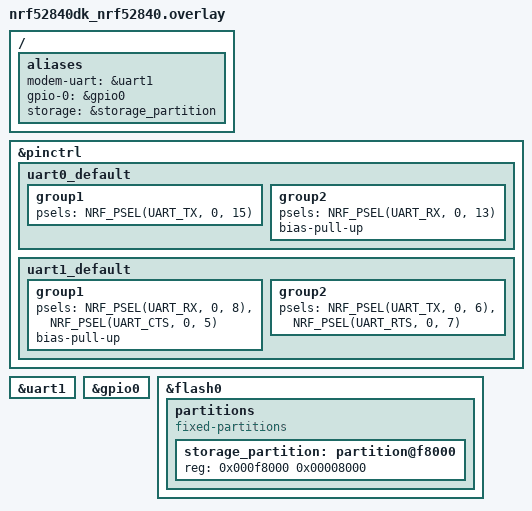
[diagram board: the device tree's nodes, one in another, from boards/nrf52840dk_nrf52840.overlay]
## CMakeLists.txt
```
# SPDX-License-Identifier: Apache-2.0

cmake_minimum_required(VERSION 3.20.0)
find_package(Zephyr REQUIRED HINTS $ENV{ZEPHYR_BASE})
project(scan_adv)

FILE(GLOB app_sources src/*.c)
target_sources(app PRIVATE ${app_sources})

add_definitions(-DDEBUG)

zephyr_library_include_directories(${ZEPHYR_BASE}/samples/bluetooth)

zephyr_library_include_directories("../../sdk/Interface")
zephyr_library_include_directories("../../sdk/sdkInc")
zephyr_library_include_directories("src")
zephyr_library_include_directories("src/MQTT")

target_sources(app PRIVATE src/osal/osal.c)
target_sources(app PRIVATE src/dev-if/dev-if.c)
target_sources(app PRIVATE src/modem-drv.c)
target_sources(app PRIVATE src/network-api.c)
target_sources(app PRIVATE src/at-commands.c)
target_sources(app PRIVATE src/httpStringBuilder.c)
target_sources(app PRIVATE src/flash-drv.c)
target_sources(app PRIVATE ../../sdk/sdkSrc/cJSON.c)
target_sources(app PRIVATE ../../sdk/sdkSrc/logger.c)
target_sources(app PRIVATE ../../sdk/sdkSrc/williotSdkJson.c)
target_sources(app PRIVATE ../../sdk/sdkSrc/upLink.c)
target_sources(app PRIVATE ../../sdk/sdkSrc/downLink.c)
target_sources(app PRIVATE ../../sdk/sdkSrc/sdkConfigurations.c)
target_sources(app PRIVATE ../../sdk/sdkSrc/mqttTopics.c)
target_sources(app PRIVATE ../../sdk/sdkSrc/networkManager.c)
target_sources(app PRIVATE ../../sdk/sdkSrc/serviceDiscovery.c)

# This for MQTT
target_sources(app PRIVATE src/MQTT/MQTTConnectClient.c)
target_sources(app PRIVATE src/MQTT/MQTTConnectServer.c)
target_sources(app PRIVATE src/MQTT/MQTTDeserializePublish.c)
target_sources(app PRIVATE src/MQTT/MQTTFormat.c)
target_sources(app PRIVATE src/MQTT/MQTTPacket.c)
target_sources(app PRIVATE src/MQTT/MQTTSerializePublish.c)
target_sources(app PRIVATE src/MQTT/MQTTSubscribeClient.c)
target_sources(app PRIVATE src/MQTT/MQTTSubscribeServer.c)
target_sources(app PRIVATE src/MQTT/MQTTUnsubscribeClient.c)
target_sources(app PRIVATE src/MQTT/MQTTSubscribeServer.c)
target_sources(app PRIVATE src/MQTT/MQTTUnsubscribeServer.c)
```

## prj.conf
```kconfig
CONFIG_BT=y
CONFIG_BT_BROADCASTER=y
CONFIG_BT_OBSERVER=y
CONFIG_BT_DEBUG_LOG=y
CONFIG_BT_DEVICE_NAME="GatewayOfhappiness"
CONFIG_HEAP_MEM_POOL_SIZE=8192
CONFIG_UART_INTERRUPT_DRIVEN=y
CONFIG_ASSERT=y
CONFIG_EVENTS=y
CONFIG_NEWLIB_LIBC=y
CONFIG_NEWLIB_LIBC_FLOAT_PRINTF=y

CONFIG_FLASH=y
CONFIG_FLASH_MAP=y
CONFIG_MPU_ALLOW_FLASH_WRITE=y
```

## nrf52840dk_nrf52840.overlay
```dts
&pinctrl {
	uart0_default: uart0_default {
		group1 {
			psels = <NRF_PSEL(UART_TX, 0, 15)>;
		};
		group2 {
			psels = <NRF_PSEL(UART_RX, 0, 13)>;
			bias-pull-up;
		};
	};

	uart1_default: uart1_default {
		group1 {
			psels = <NRF_PSEL(UART_RX, 0, 8)>,
				<NRF_PSEL(UART_CTS, 0, 5)>;
			bias-pull-up;
		};
		group2 {
			psels = <NRF_PSEL(UART_TX, 0, 6)>,
				<NRF_PSEL(UART_RTS, 0, 7)>;
		};
	};

};

&uart1{
	label = "MODEM_UART";
	status = "okay";
};

&gpio0 {
	label = "GPIO_0";
	status = "okay";
};

&flash0 {

	partitions {
		compatible = "fixed-partitions";
		#address-cells = <1>;
		#size-cells = <1>;

		storage_partition: partition@f8000 {
			label = "storage";
			status = "okay";
			reg = <0x000f8000 0x00008000>;
		};
	};
};
```

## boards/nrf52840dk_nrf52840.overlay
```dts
/ {
    aliases {
        modem-uart = &uart1;
        gpio-0 = &gpio0;
        storage = &storage_partition;
    };
};

&pinctrl {
	uart0_default: uart0_default {
		group1 {
			psels = <NRF_PSEL(UART_TX, 0, 15)>;
		};
		group2 {
			psels = <NRF_PSEL(UART_RX, 0, 13)>;
			bias-pull-up;
		};
	};

	uart1_default: uart1_default {
		group1 {
			psels = <NRF_PSEL(UART_RX, 0, 8)>,
				<NRF_PSEL(UART_CTS, 0, 5)>;
			bias-pull-up;
		};
		group2 {
			psels = <NRF_PSEL(UART_TX, 0, 6)>,
				<NRF_PSEL(UART_RTS, 0, 7)>;
		};
	};

};

&uart1{
	status = "okay";
};

&gpio0 {
	status = "okay";
};

&flash0 {

	partitions {
		compatible = "fixed-partitions";
		#address-cells = <1>;
		#size-cells = <1>;

		storage_partition: partition@f8000 {
			status = "okay";
			reg = <0x000f8000 0x00008000>;
		};
	};
};
```

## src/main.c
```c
/* main.c - Application main entry point */

/*
 * Copyright (c) 2015-2016 Intel Corporation
 *
 * SPDX-License-Identifier: Apache-2.0
 */
#include <stdio.h>
#include <stdint.h>
#include <stddef.h>
#include <assert.h>

#include <zephyr/types.h>
#include <zephyr/sys/util.h>
#include <zephyr/bluetooth/bluetooth.h>
#include <zephyr/bluetooth/hci.h>

#include "osal.h"
#include "dev-if.h"
#include "network-api.h"
#include "williotSdkJson.h"
#include "logger.h"
#include "upLink.h"
#include "downLink.h"
#include "sdkConfigurations.h"
#include "mqttTopics.h"
#include "networkManager.h"

void main(void)
{
	dev_handle localDevHandle;
	dev_handle bleDevHandle;
	SDK_STAT sdkStatus = 0;

	OsalInit(); // System initialization starts here

	sdkStatus = ConfigurationInit();
	assert(sdkStatus == SDK_SUCCESS);

	// We are expecting NULL because we don't have any local device on current platform.
	localDevHandle = DevInit(DEV_LOCAL_FIRST);
	// assert(localDevHandle);

	bleDevHandle = DevInit(DEV_BLE);
	assert(bleDevHandle);

	sdkStatus = JsonHooksInit();
	assert(sdkStatus == SDK_SUCCESS);

	sdkStatus = UpLinkInit(bleDevHandle, localDevHandle);
	assert(sdkStatus == SDK_SUCCESS);

	sdkStatus = LoggerInit();
	assert(sdkStatus == SDK_SUCCESS);

	sdkStatus = DownLinkInit(bleDevHandle, localDevHandle);
	assert(sdkStatus == SDK_SUCCESS);

	sdkStatus = NetworkManagerInit();
	assert(sdkStatus == SDK_SUCCESS);
	
    sdkStatus = NetworkInit();
    assert(sdkStatus == SDK_SUCCESS);

	OsalStart(); // System therads released here

	OsalSleep(UINT32_MAX);
}
```

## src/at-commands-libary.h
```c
#ifndef _AT_COMMANDS_LIBARY_H
#define _AT_COMMANDS_LIBARY_H

typedef enum{
    MODE_DISABLE_TIME_ZONE_CHANGE           = 0,
    MODE_ENABLE_TIME_ZONE_CHANGE            = 1,
    MODE_ENABLE_EXTENDED_TIME_ZONE_CHANGE   = 2
} eModeOfTimeZoneReporting;

typedef enum{
    MODE_DISABLE_AUTOMATIC_TIME_ZONE_UPDATE                         = 0,
    MODE_ENABLE_AUTOMATIC_TIME_ZONE_UPDATE                          = 1,
    MODE_ENABLE_AUTOMATIC_TIME_ZONE_UPDATE_AND_UPDATE_LOCAL_TIME    = 3
} eModeOfAutomaticTimeZoneUpdate;

typedef enum{
    EXTENDED_CONFIGURE_RATS_SEARCHING_SEQUENCE,
    EXTENDED_CONFIGURE_RATS_TO_BE_SEARCHED,
    EXTENDED_CONFIGURE_NETWORK_SEARCH_UNDER_LTE_RAT,

    EXTENDED_CONFIGURE_NUM
} eExtendedConfigurationCommands;

typedef enum{
    PDP_TYPE_IPV4,
    PDP_TYPE_PPP,
    PDP_TYPE_IPV6,
    PDP_TYPE_IPV4V6,

    PDP_TYPE_NUM
} ePdpType;

typedef enum{
    HTTP_CONFIGURATION_PDP_CONTEXT_ID,
    HTTP_CONFIGURATION_REQUEST_HEADER,
    HTTP_CONFIGURATION_RESPOSNSE_HEADER,
    HTTP_CONFIGURATION_CONTENT_TYPE,

    HTTP_CONFIGURATION_NUM
} eHttpConfigurationCommands;

typedef enum{
    NETWORK_REGISTRATION_DISABLE = 0,
    NETWORK_REGISTRATION_ENABLE = 1,
    NETWORK_REGISTRATION_AND_LOCATION_INFORMATION_ENABLE = 2,
    NETWORK_REGISTRATION_AND_LOCATION_INFORMATION_UE_ENABLE = 4,
}eNetworkRegistrationStatus;

typedef enum{
    QUERY_LATEST_TIME_SYNCHRONIZED_THROUGH_NETWORK = 0,
    QUERY_THE_CURRENT_GMT_TIME = 1,
    QUERY_THE_CURRENT_LOCAL_TIME = 2,
}eQueryNetworkTimeMode;

typedef enum{
    MQTT_ACCESS_BUFFER_ACCESS = 0,
    MQTT_ACCESS_DIRECT_PUSH = 1,
    MQTT_ACCESS_TRANSPARENT = 2,
}eMqttAccessMode;

typedef struct{
    eModeOfTimeZoneReporting mode;
}AtCtzrParams;

typedef struct{
    eModeOfAutomaticTimeZoneUpdate mode;
}AtCtzuParams;

typedef struct{
    eExtendedConfigurationCommands cmd;
    char * mode;
    int effect;
}AtQcfgParams;

typedef struct{
    int cid;
    ePdpType type;
    char * apn;
}AtCgdcontParams;

typedef struct{
    int getImei;
}AtCgsn;

typedef struct{
    eNetworkRegistrationStatus status;
}AtCereg;

typedef struct{
    eQueryNetworkTimeMode mode;
}AtQlts;

typedef struct{
    int contextId;
    char * host;
}AtQping;

typedef struct{
    eHttpConfigurationCommands cmd;
    int value;
}AtQhttpcfg;

typedef struct{
    int urlLength;
    int urlTimeout;
}AtQhttpurl;

typedef struct{
    int postBodySize;
    int inputTimeout;
    int responseTimeout;
}AtQhttppost;

typedef struct{
    int pdpctxId;
    int sslctxId;
    int clientId;
    const char * serverAddr;
    int serverPort;
    eMqttAccessMode accessMode;
}AtQsslopen;

typedef struct{
    int clientId;
    int payloadLength;
}AtQsslsend;

typedef struct{
    int clientId;
    int receiveLength;
}AtQsslrecv;

typedef struct{
    int clientId;
    eMqttAccessMode accessMode;
}AtQiswtmd;

#endif //_AT_COMMANDS_LIBARY_H
```

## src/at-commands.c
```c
#include "at-commands.h"
#include <assert.h>
#include <string.h>

#define FULL_MESSAGE_BUFFER_SIZE    (2048)
#define COMMAND_PREFIX_SYMBOL       ('+')
#define COMMAND_READ_SYMBOL         ('?')
#define COMMAND_SEPERATE_SYMBOL     (',')
#define COMMAND_EXECUTE_SYMBOL      ('=')
#define COMMAND_STRING_SYMBOL       ('\"')
#define COMMNAD_END_OF_LINE         ("\r\n")
#define COMMAND_KEY_VALUE_SEPERATE  (':')

#define SIZE_OF_POST_PRE_RESPOND    (2)
#define RESPONSE_SIZE(size)         ((size) + SIZE_OF_POST_PRE_RESPOND)

static const char * s_atStr = "AT";

static const char * s_atCmdsTable[AT_CMD_NUM] = {
	[AT_CMD_TEST]       = "",
	[AT_CMD_QCCID]      = "QCCID",
	[AT_CMD_CTZR]       = "CTZR",
	[AT_CMD_CTZU]       = "CTZU",
    [AT_CMD_QCFG]       = "QCFG",
    [AT_CMD_CGDCONT]    = "CGDCONT",
    [AT_CMD_CGSN]       = "CGSN",
	[AT_CMD_CEREG]      = "CEREG",
	[AT_CMD_COPS]       = "COPS",
    [AT_CMD_QCSQ]       = "QCSQ",
    [AT_CMD_QLTS]       = "QLTS",
    [AT_CMD_QPING]      = "QPING",
    [AT_CMD_QHTTPCFG]   = "QHTTPCFG",
    [AT_CMD_QHTTPURL]   = "QHTTPURL",
    [AT_CMD_QHTTPPOST]  = "QHTTPPOST",
    [AT_CMD_QHTTPGET]   = "QHTTPGET",
    [AT_CMD_QHTTPPUT]   = "QHTTPPUT",
    [AT_CMD_QHTTPREAD]  = "QHTTPREAD",
    [AT_CMD_QSSLOPEN]   = "QSSLOPEN",
    [AT_CMD_QSSLSEND]   = "QSSLSEND",
    [AT_CMD_QSSLRECV]   = "QSSLRECV",
    [AT_CMD_QISWTMD]     ="QISWTMD",
};

static const char * s_atQcfgExtConfgCmndTable[EXTENDED_CONFIGURE_NUM] = {
    [EXTENDED_CONFIGURE_RATS_SEARCHING_SEQUENCE]         = "\"nwscanseq\"",
    [EXTENDED_CONFIGURE_RATS_TO_BE_SEARCHED]             = "\"nwscanmode\"",
    [EXTENDED_CONFIGURE_NETWORK_SEARCH_UNDER_LTE_RAT]    = "\"iotopmode\"",
};

static const char * s_atCgdcontPdpTypeTable[PDP_TYPE_NUM] = {
    [PDP_TYPE_IPV4]     = "\"IPV4\"",
    [PDP_TYPE_PPP]      = "\"PPP\"",
    [PDP_TYPE_IPV6]     = "\"IPV6\"",
    [PDP_TYPE_IPV4V6]   = "\"IPV4V6\"",
};

static const char * s_atQhttpcfgCmndTable[HTTP_CONFIGURATION_NUM] = {
    [HTTP_CONFIGURATION_PDP_CONTEXT_ID]     = "\"contextid\"",
    [HTTP_CONFIGURATION_REQUEST_HEADER]     = "\"requestheader\"",
    [HTTP_CONFIGURATION_RESPOSNSE_HEADER]   = "\"responseheader\"",
    [HTTP_CONFIGURATION_CONTENT_TYPE]       = "\"contenttype\""
};

static uint8_t bufferForTesting[FULL_MESSAGE_BUFFER_SIZE];

static inline int writeCtzr(const AtCmndsParams* cmndParams, int offset)
{
    return sprintf((bufferForTesting + offset), "%d", cmndParams->atCtzrParams.mode);
}

static inline int writeCtzu(const AtCmndsParams* cmndParams, int offset)
{
    return sprintf((bufferForTesting + offset), "%d", cmndParams->atCtzuParams.mode);
}

static inline int writeQcfg(const AtCmndsParams * cmndParams, int * offset)
{
    (*offset) += sprintf((bufferForTesting + (*offset)), "%s", s_atQcfgExtConfgCmndTable[cmndParams->atQcfgParams.cmd]);
    (*offset) += sprintf((bufferForTesting + (*offset)), "%c", COMMAND_SEPERATE_SYMBOL);
    (*offset) += sprintf((bufferForTesting + (*offset)), "%s", cmndParams->atQcfgParams.mode);
    (*offset) += sprintf((bufferForTesting + (*offset)), "%c", COMMAND_SEPERATE_SYMBOL);
    return sprintf((bufferForTesting + (*offset)), "%d", cmndParams->atQcfgParams.effect);
}

static inline int writeCgdcont(const AtCmndsParams * cmndParams, int * offset)
{
    (*offset) += sprintf((bufferForTesting + (*offset)), "%d", cmndParams->atCgdcontParams.cid);
    (*offset) += sprintf((bufferForTesting + (*offset)), "%c", COMMAND_SEPERATE_SYMBOL);
    (*offset) += sprintf((bufferForTesting + (*offset)), "%s", s_atCgdcontPdpTypeTable[cmndParams->atCgdcontParams.type]);
    (*offset) += sprintf((bufferForTesting + (*offset)), "%c", COMMAND_SEPERATE_SYMBOL);
    (*offset) += sprintf((bufferForTesting + (*offset)), "%c", COMMAND_STRING_SYMBOL);
    (*offset) += sprintf((bufferForTesting + (*offset)), "%s", cmndParams->atCgdcontParams.apn);
    return sprintf((bufferForTesting + (*offset)), "%c", COMMAND_STRING_SYMBOL);
}

static inline int writeCereg(const AtCmndsParams * cmndParams, int offset)
{
    return sprintf((bufferForTesting + offset), "%d", cmndParams->atCereg.status);
}

static inline int writeQlts(const AtCmndsParams * cmndParams, int offset)
{
    return sprintf((bufferForTesting + offset), "%d", cmndParams->atQlts.mode);
}

static inline int writeQping(const AtCmndsParams * cmndParams, int * offset)
{
    (*offset) += sprintf((bufferForTesting + (*offset)), "%d", cmndParams->atQping.contextId);
    (*offset) += sprintf((bufferForTesting + (*offset)), "%c", COMMAND_SEPERATE_SYMBOL);
    (*offset) += sprintf((bufferForTesting + (*offset)), "%c", COMMAND_STRING_SYMBOL);
    (*offset) += sprintf((bufferForTesting + (*offset)), "%s", cmndParams->atQping.host);
    return sprintf((bufferForTesting + (*offset)), "%c", COMMAND_STRING_SYMBOL);
}

static inline int writeQhttpcfg(const AtCmndsParams * cmndParams, int * offset)
{
    (*offset) += sprintf((bufferForTesting + (*offset)), "%s", s_atQhttpcfgCmndTable[cmndParams->atQhttpcfg.cmd]);
    (*offset) += sprintf((bufferForTesting + (*offset)), "%c", COMMAND_SEPERATE_SYMBOL);
    return sprintf((bufferForTesting + (*offset)), "%d", cmndParams->atQhttpcfg.value);
}

static inline int writeQhttpurl(const AtCmndsParams * cmndParams, int * offset)
{
    (*offset) += sprintf((bufferForTesting + (*offset)), "%d", cmndParams->atQhttpurl.urlLength);
    (*offset) += sprintf((bufferForTesting + (*offset)), "%c", COMMAND_SEPERATE_SYMBOL);
    return sprintf((bufferForTesting + (*offset)), "%d", cmndParams->atQhttpurl.urlTimeout);
}

static inline int writeQhttppost(const AtCmndsParams * cmndParams, int * offset)
{
    (*offset) += sprintf((bufferForTesting + (*offset)), "%d", cmndParams->atQhttppost.postBodySize);
    (*offset) += sprintf((bufferForTesting + (*offset)), "%c", COMMAND_SEPERATE_SYMBOL);
    (*offset) += sprintf((bufferForTesting + (*offset)), "%d", cmndParams->atQhttppost.inputTimeout);
    (*offset) += sprintf((bufferForTesting + (*offset)), "%c", COMMAND_SEPERATE_SYMBOL);
    return sprintf((bufferForTesting + (*offset)), "%d", cmndParams->atQhttppost.responseTimeout);
}

static inline int writeQhttpget(const AtCmndsParams * cmndParams, int offset)
{
    return sprintf((bufferForTesting + offset), "%d", cmndParams->atQhttpurl.urlTimeout);
}

static inline int writeQhttread(const AtCmndsParams * cmndParams, int offset)
{
    return sprintf((bufferForTesting + offset), "%d", cmndParams->atQhttpurl.urlTimeout);
}

static inline int writeQsslopen(const AtCmndsParams * cmndParams, int * offset)
{
    (*offset) += sprintf((bufferForTesting + (*offset)), "%d", cmndParams->atQsslopen.pdpctxId);
    (*offset) += sprintf((bufferForTesting + (*offset)), "%c", COMMAND_SEPERATE_SYMBOL);
    (*offset) += sprintf((bufferForTesting + (*offset)), "%d", cmndParams->atQsslopen.sslctxId);
    (*offset) += sprintf((bufferForTesting + (*offset)), "%c", COMMAND_SEPERATE_SYMBOL);
    (*offset) += sprintf((bufferForTesting + (*offset)), "%d", cmndParams->atQsslopen.clientId);
    (*offset) += sprintf((bufferForTesting + (*offset)), "%c", COMMAND_SEPERATE_SYMBOL);
    (*offset) += sprintf((bufferForTesting + (*offset)), "%c", COMMAND_STRING_SYMBOL);
    (*offset) += sprintf((bufferForTesting + (*offset)), "%s", cmndParams->atQsslopen.serverAddr);
    (*offset) += sprintf((bufferForTesting + (*offset)), "%c", COMMAND_STRING_SYMBOL);
    (*offset) += sprintf((bufferForTesting + (*offset)), "%c", COMMAND_SEPERATE_SYMBOL);
    (*offset) += sprintf((bufferForTesting + (*offset)), "%d", cmndParams->atQsslopen.serverPort);
    (*offset) += sprintf((bufferForTesting + (*offset)), "%c", COMMAND_SEPERATE_SYMBOL);
    return sprintf((bufferForTesting + (*offset)), "%d", cmndParams->atQsslopen.accessMode); 
}

static inline int writeQsslsend(const AtCmndsParams * cmndParams, int * offset)
{
    (*offset) += sprintf((bufferForTesting + (*offset)), "%d", cmndParams->atQsslsend.clientId);
    (*offset) += sprintf((bufferForTesting + (*offset)), "%c", COMMAND_SEPERATE_SYMBOL);
    return sprintf((bufferForTesting + (*offset)), "%d", cmndParams->atQsslsend.payloadLength);  
}

static inline int writeQsslrecv(const AtCmndsParams * cmndParams, int * offset)
{
    (*offset) += sprintf((bufferForTesting + (*offset)), "%d", cmndParams->atQsslrecv.clientId);
    (*offset) += sprintf((bufferForTesting + (*offset)), "%c", COMMAND_SEPERATE_SYMBOL);
    return sprintf((bufferForTesting + (*offset)), "%d", cmndParams->atQsslrecv.receiveLength);  
}

static inline int writeQiswtmd(const AtCmndsParams * cmndParams, int * offset)
{
    (*offset) += sprintf((bufferForTesting + (*offset)), "%d", cmndParams->atQiswtmd.clientId);
    (*offset) += sprintf((bufferForTesting + (*offset)), "%c", COMMAND_SEPERATE_SYMBOL);
    return sprintf((bufferForTesting + (*offset)), "%d", cmndParams->atQiswtmd.accessMode);  
}

SDK_STAT AtTestCmd()
{
    // For now not implemeted because no test commands, always fails
    // TODO: implement
    return SDK_FAILURE;
}

SDK_STAT AtReadCmd(const eAtCmds atCmd)
{
    int offset = 0;

    if(!(0 <= atCmd && atCmd < AT_CMD_NUM))
    {
        return SDK_INVALID_PARAMS;
    }
    assert(s_atCmdsTable[atCmd]);

    offset += sprintf((bufferForTesting + offset), "%s", s_atStr);
    offset += sprintf((bufferForTesting + offset), "%c", COMMAND_PREFIX_SYMBOL);
    offset += sprintf((bufferForTesting + offset), "%s", s_atCmdsTable[atCmd]);
    offset += sprintf((bufferForTesting + offset), "%c", COMMAND_READ_SYMBOL);
    offset += sprintf((bufferForTesting + offset), "%s", COMMNAD_END_OF_LINE);

    return ModemSend(bufferForTesting, offset);
}

SDK_STAT AtWriteCmd(const eAtCmds atCmd, const AtCmndsParams * cmndParams)
{
    int offset = 0;

    if(!(0 <= atCmd && atCmd < AT_CMD_NUM) || !cmndParams)
    {
      return SDK_INVALID_PARAMS;  
    }
    assert(s_atCmdsTable[atCmd]);

    offset += sprintf((bufferForTesting + offset), "%s", s_atStr);
    offset += sprintf((bufferForTesting + offset), "%c", COMMAND_PREFIX_SYMBOL);
    offset += sprintf((bufferForTesting + offset), "%s", s_atCmdsTable[atCmd]);
    offset += sprintf((bufferForTesting + offset), "%c", COMMAND_EXECUTE_SYMBOL);

    switch(atCmd)
    {
        case AT_CMD_CTZR:
            offset += writeCtzr(cmndParams, offset);
            break;

        case AT_CMD_CTZU:
            offset += writeCtzu(cmndParams, offset);
            break;

        case AT_CMD_QCFG:
            offset += writeQcfg(cmndParams, &offset);
            break;

        case AT_CMD_CGDCONT:
            offset += writeCgdcont(cmndParams, &offset);
            break;

        case AT_CMD_CEREG:
            offset += writeCereg(cmndParams, offset);
            break;

        case AT_CMD_QLTS:
            offset += writeQlts(cmndParams, offset);
            break;

        case AT_CMD_QPING:
            offset += writeQping(cmndParams, &offset);
            break;

        case AT_CMD_QHTTPCFG:
            offset += writeQhttpcfg(cmndParams, &offset);
            break;

        case AT_CMD_QHTTPURL:
            offset += writeQhttpurl(cmndParams, &offset);
            break;

        case AT_CMD_QHTTPPOST:
            offset += writeQhttppost(cmndParams, &offset);
            break;

        case AT_CMD_QHTTPGET:
            offset += writeQhttpget(cmndParams, offset);
            break;

        case AT_CMD_QHTTPPUT:
            offset += writeQhttppost(cmndParams, &offset);
        break;

        case AT_CMD_QHTTPREAD:
            offset += writeQhttread(cmndParams, offset);
            break;

        case AT_CMD_QSSLOPEN:
            offset += writeQsslopen(cmndParams, &offset);
            break;

        case AT_CMD_QSSLSEND:
            offset += writeQsslsend(cmndParams, &offset);
            break;

        case AT_CMD_QSSLRECV:
            offset += writeQsslrecv(cmndParams, &offset);
            break;

        case AT_CMD_QISWTMD:
            offset += writeQiswtmd(cmndParams, &offset);
            break;

        default:
            return SDK_INVALID_PARAMS;  
    }

    offset += sprintf((bufferForTesting + offset), "%s", COMMNAD_END_OF_LINE);

    return ModemSend(bufferForTesting, offset);
}

SDK_STAT AtExecuteCmd(const eAtCmds atCmd)
{
    int offset = 0;

    if(!(0 <= atCmd && atCmd < AT_CMD_NUM))
    {
        return SDK_INVALID_PARAMS;
    }
    assert(s_atCmdsTable[atCmd]);

    offset += sprintf((bufferForTesting + offset), "%s", s_atStr);
    if(atCmd != AT_CMD_TEST)
    {
        offset += sprintf((bufferForTesting + offset), "%c", COMMAND_PREFIX_SYMBOL);
        offset += sprintf((bufferForTesting + offset), "%s", s_atCmdsTable[atCmd]);
    }
    offset += sprintf((bufferForTesting + offset), "%s", COMMNAD_END_OF_LINE);

    return ModemSend(bufferForTesting, offset);
}

SDK_STAT atEnumToResponseString(eAtCmds atCmd, char * responseBuffer, uint16_t bufferSize)
{
    assert(s_atCmdsTable[atCmd]);
    if(atCmd >= AT_CMD_NUM || !responseBuffer || (bufferSize == 0))
    {
        return SDK_INVALID_PARAMS;
    }

    uint16_t stringSize = strlen(s_atCmdsTable[atCmd]);
    uint16_t index = 0;

    if(bufferSize <= RESPONSE_SIZE(stringSize))
    {
        return SDK_INVALID_PARAMS;
    }

    responseBuffer[index++] = COMMAND_PREFIX_SYMBOL;
    index += sprintf((responseBuffer + index), "%s",s_atCmdsTable[atCmd]);
    responseBuffer[index++] = COMMAND_KEY_VALUE_SEPERATE;
    responseBuffer[index++] = '\0';

    return SDK_SUCCESS;

}
```

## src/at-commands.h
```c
#ifndef _AT_COMMANDS_H
#define _AT_COMMANDS_H

#include "at-commands-libary.h"
#include "modem-drv.h"

#include <stdio.h>
#include <stdint.h>

#define TURN_ON_AT_CMD_ECHO         "ATE1\r\n"
#define TURN_OFF_AT_CMD_ECHO        "ATE0\r\n"

typedef enum{
    AT_CMD_TEST,
    AT_CMD_QCCID,
    AT_CMD_CTZR,
    AT_CMD_CTZU,
    AT_CMD_QCFG,
    AT_CMD_CGDCONT,
    AT_CMD_CGSN,
    AT_CMD_CEREG,
    AT_CMD_COPS,
    AT_CMD_QCSQ,
    AT_CMD_QLTS,
    AT_CMD_QPING,
    AT_CMD_QHTTPCFG,
    AT_CMD_QHTTPURL,
    AT_CMD_QHTTPPOST,
    AT_CMD_QHTTPGET,
    AT_CMD_QHTTPPUT,
    AT_CMD_QHTTPREAD,
    AT_CMD_QSSLOPEN,
    AT_CMD_QSSLSEND,
    AT_CMD_QSSLRECV,
    AT_CMD_QISWTMD,

    AT_CMD_NUM
} eAtCmds;

typedef union {
    AtCtzrParams    atCtzrParams;
    AtCtzuParams    atCtzuParams;
    AtQcfgParams    atQcfgParams;
    AtCgdcontParams atCgdcontParams;
    AtCgsn          atCgsn;
    AtCereg         atCereg;
    AtQlts          atQlts;
    AtQping         atQping;
    AtQhttpcfg      atQhttpcfg;
    AtQhttpurl      atQhttpurl;
    AtQhttppost     atQhttppost;
    AtQsslopen      atQsslopen;
    AtQsslsend      atQsslsend;
    AtQsslrecv      atQsslrecv;
    AtQiswtmd       atQiswtmd;

}AtCmndsParams;

/**
 * @brief AT type test command function
 * 
 * @return SDK_SUCCESS if command was sent succefull
 */
SDK_STAT AtTestCmd();

/**
 * @brief AT type read command function
 * 
 * @param atCmd enum of requested command
 *
 * @return SDK_INVALID_PARAMS if enum not in bounds.
 * @return SDK_FAILURE if internal bug occurred(higher level should assert).
 * @return SDK_SUCCESS if command was sent succefully.
 */
SDK_STAT AtReadCmd(const eAtCmds atCmd);

/**
 * @brief AT type write command function
 * 
 * @param atCmd enum of requested command
 * @param cmndParams pointer to parameters of command
 *
 * @return SDK_INVALID_PARAMS if enum not in bounds or null pointer.
 * @return SDK_FAILURE if internal bug occurred(higher level should assert).
 * @return SDK_SUCCESS if command was sent succefully.
 */
SDK_STAT AtWriteCmd(const eAtCmds atCmd, const AtCmndsParams * cmndParams);

/**
 * @brief AT type execution command function
 * 
 * @param atCmd enum of requested command
 *
 * @return SDK_INVALID_PARAMS if enum not in bounds.
 * @return SDK_FAILURE if internal bug occurred(higher level should assert).
 * @return SDK_SUCCESS if command was sent succefully.
 */
SDK_STAT AtExecuteCmd(const eAtCmds atCmd);

/**
 * @brief Convert enum to modem response string.
 * 
 * @param atCmd enum of requested command
 * @param responseBuffer pointer to buffer to save the response string.
 * @param bufferSize size of buffer.
 * 
 * @return SDK_INVALID_PARAMS if null ptr or at command doesnt exist or buffer size is to short.
 * @return SDK_SUCCESS if response built successfully.
 */
SDK_STAT atEnumToResponseString(eAtCmds atCmd, char * responseBuffer, uint16_t bufferSize);

#endif //_AT_COMMANDS_H
```

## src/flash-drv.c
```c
#include <zephyr/drivers/flash.h>
#include <zephyr/storage/flash_map.h>

#include "flash-drv.h"

const static struct flash_area * s_storageArea = NULL;

inline static off_t getPageOffset(eFlashPage flashPage)
{
    return (off_t)(SIZE_OF_FLASH_PAGE * flashPage);
}

SDK_STAT FlashInit()
{
    int err = 0;
    static bool isFlashOpen = false;
 
    if(!isFlashOpen)
    {
        err = flash_area_open(FLASH_AREA_ID(storage), &s_storageArea);
        isFlashOpen = true;
    }

    return (err ? SDK_FAILURE : SDK_SUCCESS);
}

SDK_STAT FlashRead(eFlashPage flashPage, void * savePageAdd)
{
    if(!savePageAdd || (flashPage >= FLASH_PAGE_NUM)) // recheck this maybe error
    {
        return SDK_INVALID_PARAMS;
    }

    int err = flash_area_read(s_storageArea, getPageOffset(flashPage), savePageAdd, SIZE_OF_FLASH_PAGE);
    if(err)
    {
        return SDK_FAILURE;
    }

    return SDK_SUCCESS;
}

SDK_STAT FlashWrite(eFlashPage flashPage, const void * loadStrAdd, size_t sizeOfLoadStr)
{
    if(!loadStrAdd || (flashPage >= FLASH_PAGE_NUM)) // recheck this maybe error
    {
        return SDK_INVALID_PARAMS;
    }

    int ans = flash_area_write(s_storageArea, getPageOffset(flashPage), loadStrAdd, sizeOfLoadStr);
    if(ans)
    {
        return SDK_FAILURE;
    }

    return SDK_SUCCESS;
}

SDK_STAT FlashErase(eFlashPage flashPage)
{
    int ans = flash_area_erase(s_storageArea, getPageOffset(flashPage), SIZE_OF_FLASH_PAGE);
    if(ans)
    {
        return SDK_FAILURE;
    }

    return SDK_SUCCESS;
}
```

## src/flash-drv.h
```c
#ifndef _FLASH_DRV_H_
#define _FLASH_DRV_H_

#include "sdk_common.h"

#define SIZE_OF_WORD                (4)
#define SIZE_OF_FLASH_PAGE          (4096)

typedef enum{
    FLASH_PAGE_CONFIGURATION,
    FLASH_PAGE_TOKENS,

    FLASH_PAGE_NUM
} eFlashPage;

/**
 * @brief Initialize the Flash driver.
 * 
 * @return SDK_FAILURE if flash failed to open
 * @return SDK_SUCCESS if flash opened successfully.
 */
SDK_STAT FlashInit();

/**
 * @brief Read page from flash.
 * 
 * @param flashPage enum of the requested flash page.
 * @param savePageAdd pointer to buffer to store the readen page.
 * 
 * @return SDK_INVALID_PARAMS if null ptr or bad page was passed.
 * @return SDK_FAILURE if internal flash error accord.
 * @return SDK_SUCCESS if initialized successfully.
 */
SDK_STAT FlashRead(eFlashPage flashPage, void * savePageAdd);

/**
 * @brief Write page to flash.
 * 
 * @param flashPage enum of the requested flash page.
 * @param loadStrAdd pointer to buffer that have data to write.
 * @param sizeOfLoadStr size of data to write.
 * 
 * @return SDK_INVALID_PARAMS if null ptr or bad page was passed.
 * @return SDK_FAILURE if internal flash error accord.
 * @return SDK_SUCCESS if initialized successfully.
 */
SDK_STAT FlashWrite(eFlashPage flashPage, const void * loadStrAdd, size_t sizeOfLoadStr);

/**
 * @brief Erase page from flash.
 * 
 * @param flashPage enum of the requested flash page.
 * 
 * @return SDK_FAILURE if internal flash error accord.
 * @return SDK_SUCCESS if initialized successfully.
 */
SDK_STAT FlashErase(eFlashPage flashPage);

#endif //_FLASH_DRV_H_
```

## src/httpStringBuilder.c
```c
#include <stdio.h>
#include <assert.h>
#include "httpStringBuilder.h"

#define SIZE_OF_HTTP_MSG        (2048)

#define STR_SPACE               (' ')
#define STR_CRLF                ("\r\n")
#define STR_END                 ('\0')
#define HTTP_VER                ("HTTP/1.1")

typedef enum{
    HTTP_MSG_TYPE_POST,
    HTTP_MSG_TYPE_PUT,

    HTTP_MSG_TYPE_NUM
}eHttpMsgType;

static const char * s_httpMsgTypetable[HTTP_MSG_TYPE_NUM] = {
    [HTTP_MSG_TYPE_POST]         = "POST",
    [HTTP_MSG_TYPE_PUT]          = "PUT",
};

static char* buildHttpMsg(eHttpMsgType httpMsgType, char* urlExtenstion,const char** headers, uint16_t headersSize, const char* body)
{
    if(httpMsgType >= HTTP_MSG_TYPE_NUM)
    {
        return NULL;
    }

    static char s_httpMsg[SIZE_OF_HTTP_MSG] = {0};
    int index = 0;

    index += sprintf((s_httpMsg + index),"%s",s_httpMsgTypetable[httpMsgType]);
    index += sprintf((s_httpMsg + index),"%c",STR_SPACE);

    if(urlExtenstion)
    {
        index += sprintf((s_httpMsg + index),"%s",urlExtenstion);
        index += sprintf((s_httpMsg + index),"%c",STR_SPACE);
    }

    index += sprintf((s_httpMsg + index),HTTP_VER);
    index += sprintf((s_httpMsg + index),STR_CRLF);

    if(headersSize)
    {
        assert(headers);
        for(uint16_t i = 0;i < headersSize; i++)
        {
            assert(headers[i]);
            index += sprintf((s_httpMsg + index),"%s",headers[i]);
            index += sprintf((s_httpMsg + index),STR_CRLF);
        }
    }

    index += sprintf((s_httpMsg + index),STR_CRLF);

    if(body)
    {
        index += sprintf((s_httpMsg + index),"%s",body);
        index += sprintf((s_httpMsg + index),STR_CRLF); 
    }

    index += sprintf((s_httpMsg + index),"%c",STR_END);

    return s_httpMsg;

}

char* BuildHttpPostMsg(char* urlExtenstion, const char** headers, uint16_t headersSize, const char* body)
{
    return buildHttpMsg(HTTP_MSG_TYPE_POST, urlExtenstion, headers, headersSize, body);
}

char* BuildHttpPutMsg(char* urlExtenstion, const char** headers, uint16_t headersSize, const char* body)
{
    return buildHttpMsg(HTTP_MSG_TYPE_PUT, urlExtenstion, headers, headersSize, body);
}
```

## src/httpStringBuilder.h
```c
#ifndef _HTTP_STRING_BUILDER_H
#define _HTTP_STRING_BUILDER_H

#include <stdint.h>
/**
 * @brief Build http post message.
 * 
 * @param urlExtenstion url extenstion of the msg.
 * @param headers pointer to buffer of headers.
 * @param headersSize number of headers.
 * @param body the body of the message
 * 
 * @return NULL if internal failt, otherwise the http ready string.
 */
char* BuildHttpPostMsg(char* urlExtenstion, const char** headers, uint16_t headersSize, const char* body);

/**
 * @brief Build http put message.
 * 
 * @param urlExtenstion url extenstion of the msg.
 * @param headers pointer to buffer of headers.
 * @param headersSize number of headers.
 * @param body the body of the message
 * 
 * @return NULL if internal failt, otherwise the http ready string.
 */
char* BuildHttpPutMsg(char* urlExtenstion, const char** headers, uint16_t headersSize, const char* body);
#endif //_HTTP_STRING_BUILDER_H
```

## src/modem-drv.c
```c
#include "modem-drv.h"
#include "osal.h"

#include <assert.h>
#include <zephyr/kernel.h>
#include <zephyr/device.h>
#include <zephyr/devicetree.h>
#include <zephyr/drivers/uart.h>
#include <zephyr/drivers/gpio.h>

#include "logger.h"

#define PIN_CATM_EN                                         (25)
#define PIN_PWRKET_MCU                                      (26)

#define KERNEL_STACK_SIZE                                   (4096)
#define UART_RX_MSGQ_SIZE                                   (128)
#define UART_TX_MSGQ_SIZE                                   (128)
#define PROTOCOL_MAX_MSG_SIZE                               (2048)
#define INITAL_COUNT                                        (0)
#define COUNT_LIMIT                                         (1)

#define INPUT_STRING_FIRST                                  '>'
#define INPUT_STRING_SECOND                                 ' '
#define SIZE_OF_INPUT_STRING                                (2)
#define IS_NORMAL_MSG_RECEIVED(msgBuf,msgSize)              ((msgBuf)[(msgSize) - 1] == '\n') 
#define IS_INPUT_MSG_RECEIVED(msgBuf,msgSize)               (((msgSize) == SIZE_OF_INPUT_STRING) && \
                                                                ((msgBuf)[(msgSize) - 2] == INPUT_STRING_FIRST) && \
                                                                ((msgBuf)[(msgSize) - 1] == INPUT_STRING_SECOND))
#define IS_MSG_TOO_LONG(msgSize)                            ((msgSize) == PROTOCOL_MAX_MSG_SIZE)


static const struct device* s_uartDev;
static struct k_thread s_uartReadThread;
static K_KERNEL_STACK_DEFINE(s_uartReadThreadStack, KERNEL_STACK_SIZE);
static K_SEM_DEFINE(s_txSendSem, INITAL_COUNT, COUNT_LIMIT);

static uint8_t s_uartRxMsgqBuf[UART_RX_MSGQ_SIZE];
static struct k_msgq s_uartRxMsgq;

static uint8_t* s_uartTxMsgqBuf;
static uint16_t s_txBufSize = 0;
static ReadModemDataCB s_modemReadFunc = NULL;

static void processRead()
{
    uint8_t byte = 0;
    int bytesRead = 0;

    // Copy all FIFO contents to the message queue
    do {
        bytesRead = uart_fifo_read(s_uartDev, &byte, 1);
        __ASSERT((bytesRead >= 0),"Received error from uart_fifo_read");

        if (bytesRead > 0)
        {
            // remove print after finish testing
            k_msgq_put(&s_uartRxMsgq, &byte, K_NO_WAIT);
        }
    } while (bytesRead > 0);
}

static void processSend()
{
    int bytesSent = 0;
    static int s_bytesOffset = 0;

    bytesSent = uart_fifo_fill(s_uartDev, s_uartTxMsgqBuf + s_bytesOffset, s_txBufSize);
    __ASSERT((bytesSent >= 0),"Received error from uart_fifo_fill");

    if(bytesSent < s_txBufSize)
    {
        s_bytesOffset += bytesSent;
        s_txBufSize -= bytesSent;                
    }
    else
    {
        s_bytesOffset = 0;
        uart_irq_tx_disable(s_uartDev);
        k_sem_give(&s_txSendSem);
    }
}

static void modemUartIsr(const struct device* dev, void* user_data) 
{
    ARG_UNUSED(dev);
    ARG_UNUSED(user_data);

    while (uart_irq_update(dev) && uart_irq_is_pending(dev)) 
    {
        if (uart_irq_tx_ready(dev)) 
        {
			processSend();
		}
		if (uart_irq_rx_ready(dev)) 
        {
			processRead();
		}
	}
}

static inline void processMessage(uint8_t* buf, int size) 
{
    __ASSERT(s_modemReadFunc, "Modem read func doesn't exist");
    s_modemReadFunc(buf, size);
}

static void uartRead(void* p1, void* p2, void* p3) 
{
    ARG_UNUSED(p1);
    ARG_UNUSED(p2);
    ARG_UNUSED(p3);
    
    static uint8_t s_msgBuf[PROTOCOL_MAX_MSG_SIZE + 1];
    
    int msgSize = 0;
    int result = 0;
    LOG_DEBUG_INTERNAL("uartRead thread running\n");
    
    while (true) {
        result = k_msgq_get(&s_uartRxMsgq, &(s_msgBuf[msgSize]), K_FOREVER);
        __ASSERT((result >= 0),"Received error from k_msgq_get");

        msgSize++;

        // Normal command
        if(IS_NORMAL_MSG_RECEIVED(s_msgBuf,msgSize)) 
        {
            s_msgBuf[msgSize-1] = '\0';
            s_msgBuf[msgSize-2] = '\0';
            processMessage(s_msgBuf, msgSize - 1);
            msgSize = 0;
        }

        // Input string command
        else if(IS_INPUT_MSG_RECEIVED(s_msgBuf,msgSize))
        {
            s_msgBuf[msgSize] = '\0';
            processMessage(s_msgBuf, msgSize);
            msgSize = 0;
        }

        // Msg too long
        else if(IS_MSG_TOO_LONG(msgSize)) 
        {
            LOG_DEBUG_INTERNAL("Malformed s_uartDev message: too large\n");
            msgSize = 0;
        }
    }
    
}

SDK_STAT ModemSend(const void* dataBuff, uint16_t buffSize)
{
    int err = 0;

    if(!dataBuff)
    {
        return SDK_INVALID_PARAMS;
    }

    s_uartTxMsgqBuf = (uint8_t*)dataBuff;
    s_txBufSize = buffSize;
	uart_irq_tx_enable(s_uartDev);

    err = k_sem_take(&s_txSendSem, K_FOREVER);
    if(err)
    {
        return SDK_FAILURE;
    }

    return SDK_SUCCESS;
}

static void modemDeviceStart()
{
    int result = 0;
    const struct device* gpioDev = DEVICE_DT_GET(DT_ALIAS(gpio_0));

    result = gpio_pin_configure(gpioDev, PIN_CATM_EN, GPIO_OUTPUT);
    __ASSERT((result >= 0),"Received error from gpio_pin_configure");
    result = gpio_pin_configure(gpioDev, PIN_PWRKET_MCU, GPIO_OUTPUT);
    __ASSERT((result >= 0),"Received error from gpio_pin_configure");

    result = gpio_pin_set(gpioDev, PIN_CATM_EN,0);
    __ASSERT((result >= 0),"Received error from gpio_pin_set");
    k_msleep(1000);
    result = gpio_pin_set(gpioDev, PIN_CATM_EN,1);
    __ASSERT((result >= 0),"Received error from gpio_pin_set");

    result = gpio_pin_set(gpioDev, PIN_PWRKET_MCU,1);
    __ASSERT((result >= 0),"Received error from gpio_pin_set");
    k_msleep(1000);
    result = gpio_pin_set(gpioDev, PIN_PWRKET_MCU,0);
    __ASSERT((result >= 0),"Received error from gpio_pin_set");
}

SDK_STAT ModemInit(ReadModemDataCB cb) 
{
    modemDeviceStart();

    s_uartDev = DEVICE_DT_GET(DT_ALIAS(modem_uart));
    if(!s_uartDev || !cb)
    {
        return SDK_FAILURE;
    }

    s_modemReadFunc = cb;
    k_msgq_init(&s_uartRxMsgq, s_uartRxMsgqBuf, 1, UART_RX_MSGQ_SIZE);
    
    k_thread_create(&s_uartReadThread, s_uartReadThreadStack, K_KERNEL_STACK_SIZEOF(s_uartReadThreadStack),
                    uartRead, NULL, NULL, NULL, CONVERTED_PRIORITY(THREAD_PRIORITY_HIGH), 0, K_NO_WAIT);

    uart_irq_callback_user_data_set(s_uartDev, modemUartIsr, NULL);
    uart_irq_rx_enable(s_uartDev);

    return SDK_SUCCESS;
}
```

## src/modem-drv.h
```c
#ifndef _MODEM_DRV_H
#define _MODEM_DRV_H

#include <stdint.h>
#include <sdk_common.h>

/**
 * @brief Function pointer for modem receive buffer received will have a '\0' at the end
 * 
 */
typedef void (*ReadModemDataCB)(uint8_t* buffer, uint16_t size);

/**
 * @brief initialize the modem message send via uart, create thread for message comming from modem.
 * 
 */
SDK_STAT ModemInit(ReadModemDataCB cb);

/**
 * @brief API to send message via uart to modem.
 * 
 * @param dataBuff pointer to buffer of message data.
 * @param buffSize size of data message buffer.
 * 
 * @return SDK_INVALID_PARAMS if bad parameters were passed.
 * @return SDK_FAILURE if internal bug occurred(higher level should assert).
 * @return SDK_SUCCESS if messaged was sent succefully.
 */
SDK_STAT ModemSend(const void* dataBuff, uint16_t buffSize);

#endif //_MODEM_DRV_H
```
